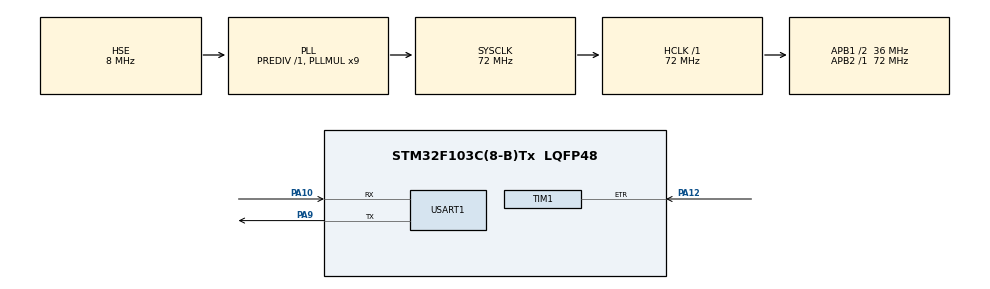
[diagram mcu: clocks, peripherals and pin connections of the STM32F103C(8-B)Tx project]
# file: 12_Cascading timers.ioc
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Mcu.Family=STM32F1
Mcu.Name=STM32F103C(8-B)Tx
Mcu.Package=LQFP48
NVIC.PriorityGroup=NVIC_PRIORITYGROUP_4
NVIC.TIM3_IRQn=true\:0\:0\:false\:false\:true\:true\:true\:true
PA10.Mode=Asynchronous
PA10.Signal=USART1_RX
PA12.Signal=S_TIM1_ETR
PA13.Mode=Serial_Wire
PA13.Signal=SYS_JTMS-SWDIO
PA14.Mode=Serial_Wire
PA14.Signal=SYS_JTCK-SWCLK
PA9.Mode=Asynchronous
PA9.Signal=USART1_TX
PD0-OSC_IN.Mode=HSE-External-Oscillator
PD0-OSC_IN.Signal=RCC_OSC_IN
PD1-OSC_OUT.Mode=HSE-External-Oscillator
PD1-OSC_OUT.Signal=RCC_OSC_OUT
ProjectManager.HeapSize=0x200
ProjectManager.StackSize=0x400
ProjectManager.TargetToolchain=STM32CubeIDE
RCC.AHBFreq_Value=72000000
RCC.APB1CLKDivider=RCC_HCLK_DIV2
RCC.APB1Freq_Value=36000000
RCC.APB1TimFreq_Value=72000000
RCC.APB2Freq_Value=72000000
RCC.APB2TimFreq_Value=72000000
RCC.HCLKFreq_Value=72000000
RCC.PLLMUL=RCC_PLL_MUL9
RCC.PLLSourceVirtual=RCC_PLLSOURCE_HSE
RCC.RCC_MCOSource=RCC_MCO1SOURCE_PLLCLK
RCC.SYSCLKFreq_VALUE=72000000
RCC.SYSCLKSource=RCC_SYSCLKSOURCE_PLLCLK
RCC.USBFreq_Value=72000000
SH.S_TIM1_ETR.0=TIM1_ETR,ClockSourceETR_Mode2
TIM1.Period=65535
TIM1.Prescaler=0
TIM1.TIM_MasterOutputTrigger=TIM_TRGO_UPDATE
TIM2.Period=65535
TIM2.TIM_MasterOutputTrigger=TIM_TRGO_UPDATE
TIM2.TIM_MasterSlaveMode=TIM_MASTERSLAVEMODE_DISABLE
TIM3.Period=1999
TIM3.Prescaler=35999
USART1.VirtualMode=VM_ASYNC
VP_TIM2_VS_ClockSourceITR.Mode=TriggerSource_ITR0
VP_TIM2_VS_ControllerModeClock.Mode=Clock Mode
VP_TIM3_VS_ClockSourceINT.Mode=Internal
board=custom

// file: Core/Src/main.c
/* USER CODE BEGIN Header */
/**
  ******************************************************************************
  * @file           : main.c
  * @brief          : Main program body
  ******************************************************************************
  * @attention
  *
  * Copyright (c) 2022 STMicroelectronics.
  * All rights reserved.
  *
  * This software is licensed under terms that can be found in the LICENSE file
  * in the root directory of this software component.
  * If no LICENSE file comes with this software, it is provided AS-IS.
  *
  ******************************************************************************
  */
/* USER CODE END Header */
#include "main.h"

/* USER CODE BEGIN Includes */
#include "stdio_usart.h"
#include <inttypes.h>
/* USER CODE END Includes */

 TIM_HandleTypeDef htim1;
TIM_HandleTypeDef htim2;
TIM_HandleTypeDef htim3;

UART_HandleTypeDef huart1;

/* USER CODE BEGIN PV */
uint8_t read_flag = 0;
/* USER CODE END PV */

void SystemClock_Config(void);
static void MX_GPIO_Init(void);
static void MX_TIM1_Init(void);
static void MX_TIM2_Init(void);
static void MX_TIM3_Init(void);
static void MX_USART1_UART_Init(void);

int main(void)
{

  /* MCU Configuration--------------------------------------------------------*/

  /* Reset of all peripherals, Initializes the Flash interface and the Systick. */
  HAL_Init();

  /* Configure the system clock */
  SystemClock_Config();

  /* Initialize all configured peripherals */
  MX_GPIO_Init();
  MX_TIM1_Init();
  MX_TIM2_Init();
  MX_TIM3_Init();
  MX_USART1_UART_Init();
  /* USER CODE BEGIN 2 */
	RetargetInit(&huart1);				// initializing the stdio retargetting

	HAL_TIM_Base_Start(&htim1);			// start TIM1
	HAL_TIM_Base_Start(&htim2);			// start TIM2
	HAL_TIM_Base_Start_IT(&htim3);		// start TIM3

	float frequency;
	uint32_t counterLS;
	uint32_t counterMS;
  /* USER CODE END 2 */

  /* Infinite loop */
  /* USER CODE BEGIN WHILE */
  while (1)
  {
		if(read_flag)
		{
		    /* Clear the read flag */
			read_flag = 0;

			counterLS = __HAL_TIM_GetCounter(&htim1);													//Get the counter value of Timer1
			counterMS = __HAL_TIM_GetCounter(&htim2);													//Get the counter value of Timer2
			frequency = (float)((counterMS * __HAL_TIM_GetAutoreload(&htim1)) + counterLS) / 1000000;	//Calculate the frequency of the input signal
			__HAL_TIM_SetCounter(&htim1, 0);															//Reset the counter value of Timer1
			__HAL_TIM_SetCounter(&htim2, 0);															//Reset the counter value of Timer2
			printf("frequency is %2.6f MHz\r\n", frequency);											//Print the frequency
			/* print the number of pulses counted */
			printf("n. of pulses is %lu \r\n\r\n", (counterMS * __HAL_TIM_GetAutoreload(&htim1)) + counterLS);
		}

//		printf("TIM4:   %lu \r\n", (__HAL_TIM_GetCounter(&htim4)));
//		printf("TIM3:   %lu \r\n", (__HAL_TIM_GetCounter(&htim3)));
//		printf("TIM2:   %lu \r\n", (__HAL_TIM_GetCounter(&htim2)));
//		printf("TIM1:   %lu \r\n\r\n", (__HAL_TIM_GetCounter(&htim1)));
    /* USER CODE END WHILE */

  }
}

void SystemClock_Config(void)
{
  RCC_OscInitTypeDef RCC_OscInitStruct = {0};
  RCC_ClkInitTypeDef RCC_ClkInitStruct = {0};

  /** Initializes the RCC Oscillators according to the specified parameters
  * in the RCC_OscInitTypeDef structure.
  */
  RCC_OscInitStruct.OscillatorType = RCC_OSCILLATORTYPE_HSE;
  RCC_OscInitStruct.HSEState = RCC_HSE_ON;
  RCC_OscInitStruct.HSEPredivValue = RCC_HSE_PREDIV_DIV1;
  RCC_OscInitStruct.HSIState = RCC_HSI_ON;
  RCC_OscInitStruct.PLL.PLLState = RCC_PLL_ON;
  RCC_OscInitStruct.PLL.PLLSource = RCC_PLLSOURCE_HSE;
  RCC_OscInitStruct.PLL.PLLMUL = RCC_PLL_MUL9;
  if (HAL_RCC_OscConfig(&RCC_OscInitStruct) != HAL_OK)
  {
    Error_Handler();
  }

  /** Initializes the CPU, AHB and APB buses clocks
  */
  RCC_ClkInitStruct.ClockType = RCC_CLOCKTYPE_HCLK|RCC_CLOCKTYPE_SYSCLK
                              |RCC_CLOCKTYPE_PCLK1|RCC_CLOCKTYPE_PCLK2;
  RCC_ClkInitStruct.SYSCLKSource = RCC_SYSCLKSOURCE_PLLCLK;
  RCC_ClkInitStruct.AHBCLKDivider = RCC_SYSCLK_DIV1;
  RCC_ClkInitStruct.APB1CLKDivider = RCC_HCLK_DIV2;
  RCC_ClkInitStruct.APB2CLKDivider = RCC_HCLK_DIV1;

  if (HAL_RCC_ClockConfig(&RCC_ClkInitStruct, FLASH_LATENCY_2) != HAL_OK)
  {
    Error_Handler();
  }
}

static void MX_TIM1_Init(void)
{

  TIM_ClockConfigTypeDef sClockSourceConfig = {0};
  TIM_MasterConfigTypeDef sMasterConfig = {0};

  htim1.Instance = TIM1;
  htim1.Init.Prescaler = 0;
  htim1.Init.CounterMode = TIM_COUNTERMODE_UP;
  htim1.Init.Period = 65535;
  htim1.Init.ClockDivision = TIM_CLOCKDIVISION_DIV1;
  htim1.Init.RepetitionCounter = 0;
  htim1.Init.AutoReloadPreload = TIM_AUTORELOAD_PRELOAD_DISABLE;
  if (HAL_TIM_Base_Init(&htim1) != HAL_OK)
  {
    Error_Handler();
  }
  sClockSourceConfig.ClockSource = TIM_CLOCKSOURCE_ETRMODE2;
  sClockSourceConfig.ClockPolarity = TIM_CLOCKPOLARITY_NONINVERTED;
  sClockSourceConfig.ClockPrescaler = TIM_CLOCKPRESCALER_DIV1;
  sClockSourceConfig.ClockFilter = 0;
  if (HAL_TIM_ConfigClockSource(&htim1, &sClockSourceConfig) != HAL_OK)
  {
    Error_Handler();
  }
  sMasterConfig.MasterOutputTrigger = TIM_TRGO_UPDATE;
  sMasterConfig.MasterSlaveMode = TIM_MASTERSLAVEMODE_DISABLE;
  if (HAL_TIMEx_MasterConfigSynchronization(&htim1, &sMasterConfig) != HAL_OK)
  {
    Error_Handler();
  }

}

static void MX_TIM2_Init(void)
{

  TIM_SlaveConfigTypeDef sSlaveConfig = {0};
  TIM_MasterConfigTypeDef sMasterConfig = {0};

  htim2.Instance = TIM2;
  htim2.Init.Prescaler = 0;
  htim2.Init.CounterMode = TIM_COUNTERMODE_UP;
  htim2.Init.Period = 65535;
  htim2.Init.ClockDivision = TIM_CLOCKDIVISION_DIV1;
  htim2.Init.AutoReloadPreload = TIM_AUTORELOAD_PRELOAD_DISABLE;
  if (HAL_TIM_Base_Init(&htim2) != HAL_OK)
  {
    Error_Handler();
  }
  sSlaveConfig.SlaveMode = TIM_SLAVEMODE_EXTERNAL1;
  sSlaveConfig.InputTrigger = TIM_TS_ITR0;
  if (HAL_TIM_SlaveConfigSynchro(&htim2, &sSlaveConfig) != HAL_OK)
  {
    Error_Handler();
  }
  sMasterConfig.MasterOutputTrigger = TIM_TRGO_UPDATE;
  sMasterConfig.MasterSlaveMode = TIM_MASTERSLAVEMODE_DISABLE;
  if (HAL_TIMEx_MasterConfigSynchronization(&htim2, &sMasterConfig) != HAL_OK)
  {
    Error_Handler();
  }

}

static void MX_TIM3_Init(void)
{

  TIM_ClockConfigTypeDef sClockSourceConfig = {0};
  TIM_MasterConfigTypeDef sMasterConfig = {0};

  htim3.Instance = TIM3;
  htim3.Init.Prescaler = 35999;
  htim3.Init.CounterMode = TIM_COUNTERMODE_UP;
  htim3.Init.Period = 1999;
  htim3.Init.ClockDivision = TIM_CLOCKDIVISION_DIV1;
  htim3.Init.AutoReloadPreload = TIM_AUTORELOAD_PRELOAD_DISABLE;
  if (HAL_TIM_Base_Init(&htim3) != HAL_OK)
  {
    Error_Handler();
  }
  sClockSourceConfig.ClockSource = TIM_CLOCKSOURCE_INTERNAL;
  if (HAL_TIM_ConfigClockSource(&htim3, &sClockSourceConfig) != HAL_OK)
  {
    Error_Handler();
  }
  sMasterConfig.MasterOutputTrigger = TIM_TRGO_RESET;
  sMasterConfig.MasterSlaveMode = TIM_MASTERSLAVEMODE_DISABLE;
  if (HAL_TIMEx_MasterConfigSynchronization(&htim3, &sMasterConfig) != HAL_OK)
  {
    Error_Handler();
  }

}

static void MX_USART1_UART_Init(void)
{

  huart1.Instance = USART1;
  huart1.Init.BaudRate = 115200;
  huart1.Init.WordLength = UART_WORDLENGTH_8B;
  huart1.Init.StopBits = UART_STOPBITS_1;
  huart1.Init.Parity = UART_PARITY_NONE;
  huart1.Init.Mode = UART_MODE_TX_RX;
  huart1.Init.HwFlowCtl = UART_HWCONTROL_NONE;
  huart1.Init.OverSampling = UART_OVERSAMPLING_16;
  if (HAL_UART_Init(&huart1) != HAL_OK)
  {
    Error_Handler();
  }

}

static void MX_GPIO_Init(void)
{

  /* GPIO Ports Clock Enable */
  __HAL_RCC_GPIOD_CLK_ENABLE();
  __HAL_RCC_GPIOA_CLK_ENABLE();

}

/* USER CODE BEGIN 4 */
void HAL_TIM_PeriodElapsedCallback(TIM_HandleTypeDef* htim)
{
	read_flag = 1;		// set the read flag signal
}
/* USER CODE END 4 */

void Error_Handler(void)
{
  __disable_irq();
  while (1)
  {
  }
}
